# MKV31F51212 register map
Vendor: Freescale Semiconductor, Inc.; Series: Kinetis_V; File version: 1.6
CPU: CM4 r0p1, little endian, no MPU, FPU, VTOR, 4 interrupt priority bits
Registers are 32-bit, read-write, reset 0x0 unless marked. A register's access mark holds for its fields unless they carry their own. Offsets are from the block's base; [hi:lo] are bit positions; {n}, {i} and the like mark numbered series.

## FTFA_FlashConfig — Flash configuration field
Base 0x00000400; register names take the prefix NV_
0x00 BACKKEY3 8-bit ro reset 0xFF — Backdoor Comparison Key 3.
  [7:0] KEY — Backdoor Comparison Key.
0x01 BACKKEY2 8-bit ro reset 0xFF — Backdoor Comparison Key 2.
  [7:0] KEY — Backdoor Comparison Key.
0x02 BACKKEY1 8-bit ro reset 0xFF — Backdoor Comparison Key 1.
  [7:0] KEY — Backdoor Comparison Key.
0x03 BACKKEY0 8-bit ro reset 0xFF — Backdoor Comparison Key 0.
  [7:0] KEY — Backdoor Comparison Key.
0x04 BACKKEY7 8-bit ro reset 0xFF — Backdoor Comparison Key 7.
  [7:0] KEY — Backdoor Comparison Key.
0x05 BACKKEY6 8-bit ro reset 0xFF — Backdoor Comparison Key 6.
  [7:0] KEY — Backdoor Comparison Key.
0x06 BACKKEY5 8-bit ro reset 0xFF — Backdoor Comparison Key 5.
  [7:0] KEY — Backdoor Comparison Key.
0x07 BACKKEY4 8-bit ro reset 0xFF — Backdoor Comparison Key 4.
  [7:0] KEY — Backdoor Comparison Key.
0x08 FPROT3 8-bit ro reset 0xFF — Non-volatile P-Flash Protection 1 - Low Register
  [7:0] PROT — P-Flash Region Protect
0x09 FPROT2 8-bit ro reset 0xFF — Non-volatile P-Flash Protection 1 - High Register
  [7:0] PROT — P-Flash Region Protect
0x0A FPROT1 8-bit ro reset 0xFF — Non-volatile P-Flash Protection 0 - Low Register
  [7:0] PROT — P-Flash Region Protect
0x0B FPROT0 8-bit ro reset 0xFF — Non-volatile P-Flash Protection 0 - High Register
  [7:0] PROT — P-Flash Region Protect
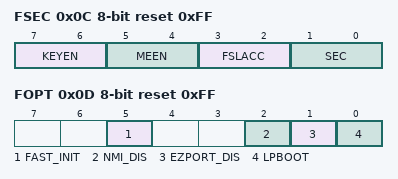
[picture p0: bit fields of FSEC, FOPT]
0x0C FSEC 8-bit ro reset 0xFF — Non-volatile Flash Security Register
  [7:6] KEYEN — Backdoor Key Security Enable
    2=Backdoor key access enabled; 3=Backdoor key access disabled
  [5:4] MEEN
    2=Mass erase is disabled; 3=Mass erase is enabled
  [3:2] FSLACC — Freescale Failure Analysis Access Code
    2=Freescale factory access denied; 3=Freescale factory access granted
  [1:0] SEC — Flash Security
    2=MCU security status is unsecure; 3=MCU security status is secure
0x0D FOPT 8-bit ro reset 0xFF — Non-volatile Flash Option Register
  [5] FAST_INIT
    0=Slower initialization; 1=Fast Initialization
  [2] NMI_DIS
    0=NMI interrupts are always blocked; 1=NMI_b pin/interrupts reset default to enabled
  [1] EZPORT_DIS
    0=EzPort operation is disabled; 1=EzPort operation is enabled
  [0] LPBOOT
    0=Low-power boot; 1=Normal boot

## DMAMUX — DMA channel multiplexor
Base 0x40021000; register names take the prefix DMAMUX_
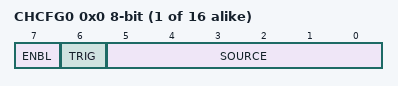
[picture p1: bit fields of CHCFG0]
{0x0+i} CHCFG{i} (i=0..15) 8-bit — Channel Configuration register
  [7] ENBL — DMA Channel Enable
    0=DMA channel is disabled. This mode is primarily used during configuration of the DMAMux. The DMA has separate channel enables/disables, which should be used to disable or reconfigure a DMA channel.; 1=DMA channel is enabled
  [6] TRIG — DMA Channel Trigger Enable
    0=Triggering is disabled. If triggering is disabled and ENBL is set, the DMA Channel will simply route the specified source to the DMA channel. (Normal mode); 1=Triggering is enabled. If triggering is enabled and ENBL is set, the DMAMUX is in Periodic Trigger mode.
  [5:0] SOURCE — DMA Channel Source (Slot)

## RNG — Random Number Generator Accelerator
Base 0x40029000; register names take the prefix RNG_
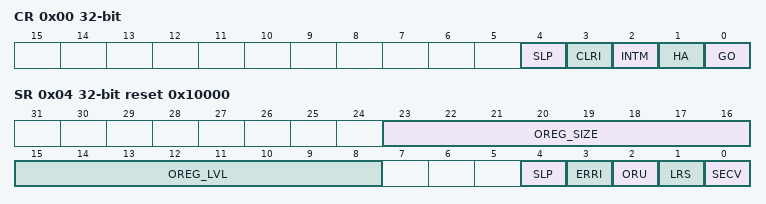
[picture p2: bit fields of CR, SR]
0x00 CR — RNGA Control Register
  [4] SLP — Sleep
    0=Normal mode; 1=Sleep (low-power) mode
  [3] CLRI wo — Clear Interrupt
    0=Do not clear the interrupt; 1=Clear the interrupt. When you write 1 to this field, RNGA then resets the error-interrupt indicator (SR[ERRI]). This bit always reads as 0.
  [2] INTM — Interrupt Mask
    0=Not masked; 1=Masked
  [1] HA — High Assurance
    0=Disabled; 1=Enabled
  [0] GO
    0=Disabled; 1=Enabled
0x04 SR ro reset 0x10000 — RNGA Status Register
  [23:16] OREG_SIZE — Output Register Size
    1=One word (this value is fixed)
  [15:8] OREG_LVL — Output Register Level
    0=No words (empty); 1=One word (valid)
  [4] SLP — Sleep
    0=Normal mode; 1=Sleep (low-power) mode
  [3] ERRI — Error Interrupt
    0=No underflow; 1=Underflow
  [2] ORU — Output Register Underflow
    0=No underflow; 1=Underflow
  [1] LRS — Last Read Status
    0=No underflow; 1=Underflow
  [0] SECV — Security Violation
    0=No security violation; 1=Security violation
0x08 ER wo — RNGA Entropy Register
  [31:0] EXT_ENT — External Entropy
0x0C OR ro — RNGA Output Register
  [31:0] RANDOUT — Random Output
    0=Invalid data (if you read this field when it is 0 and SR[OREG_LVL] is 0, RNGA then writes 1 to SR[ERRI], SR[ORU], and SR[LRS]; when the error interrupt is not masked (CR[INTM]=0), RNGA also asserts an error interrupt request to the interrupt controller)
